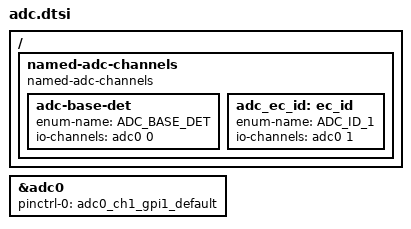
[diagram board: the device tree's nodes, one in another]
/* Copyright 2023 The ChromiumOS Authors
 * Use of this source code is governed by a BSD-style license that can be
 * found in the LICENSE file.
 */

/ {
	named-adc-channels {
		compatible = "named-adc-channels";

		adc-base-det {
			enum-name = "ADC_BASE_DET";
			io-channels = <&adc0 0>;
		};
		adc_ec_id: ec_id {
			enum-name = "ADC_ID_1";
			io-channels = <&adc0 1>;
		};
	};
};

&adc0 {
	status = "okay";
	pinctrl-0 = <&adc0_ch1_gpi1_default>;
	pinctrl-names = "default";
};
